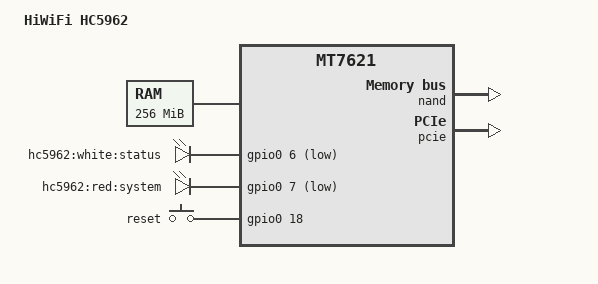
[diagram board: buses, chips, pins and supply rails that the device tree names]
/dts-v1/;

#include "mt7621.dtsi"

#include <dt-bindings/gpio/gpio.h>
#include <dt-bindings/input/input.h>

/ {
	compatible = "hiwifi,hc5962", "mediatek,mt7621-soc";
	model = "HiWiFi HC5962";

	aliases {
		led-boot = &led_system;
		led-failsafe = &led_system;
		led-running = &led_status;
		led-upgrade = &led_status;
	};

	memory@0 {
		device_type = "memory";
		reg = <0x0 0x10000000>;
	};

	chosen {
		bootargs = "console=ttyS0,115200";
	};

	leds {
		compatible = "gpio-leds";

		led_status: status {
			label = "hc5962:white:status";
			gpios = <&gpio0 6 GPIO_ACTIVE_LOW>;
		};

		led_system: system {
			label = "hc5962:red:system";
			gpios = <&gpio0 7 GPIO_ACTIVE_LOW>;
			panic-indicator;
		};
	};

	keys {
		compatible = "gpio-keys-polled";
		poll-interval = <20>;

		reset {
			label = "reset";
			gpios = <&gpio0 18 GPIO_ACTIVE_HIGH>;
			linux,code = <KEY_RESTART>;
		};
	};
};

&nand {
	status = "okay";

	partitions {
		compatible = "fixed-partitions";
		#address-cells = <1>;
		#size-cells = <1>;

		partition@0 {
			label = "u-boot";
			reg = <0x0 0x80000>;
			read-only;
		};

		partition@80000 {
			label = "debug";
			reg = <0x80000 0x80000>;
			read-only;
		};

		factory: partition@100000 {
			label = "factory";
			reg = <0x100000 0x40000>;
			read-only;
		};

		partition@140000 {
			label = "kernel";
			reg = <0x140000 0x200000>;
		};

		partition@340000 {
			label = "ubi";
			reg = <0x340000 0x7C40000>;
		};
	};
};

&pcie {
	status = "okay";
};

&pcie0 {
	mt76@0,0 {
		reg = <0x0000 0 0 0 0>;
		mediatek,mtd-eeprom = <&factory 0x0000>;
		ieee80211-freq-limit = <2400000 2500000>;
	};
};

&pcie1 {
	mt76@0,0 {
		reg = <0x0000 0 0 0 0>;
		mediatek,mtd-eeprom = <&factory 0x8000>;
		ieee80211-freq-limit = <5000000 6000000>;
	};
};

&pinctrl {
	state_default: pinctrl0 {
		gpio {
			ralink,group = "uart3", "jtag";
			ralink,function = "gpio";
		};
	};
};
